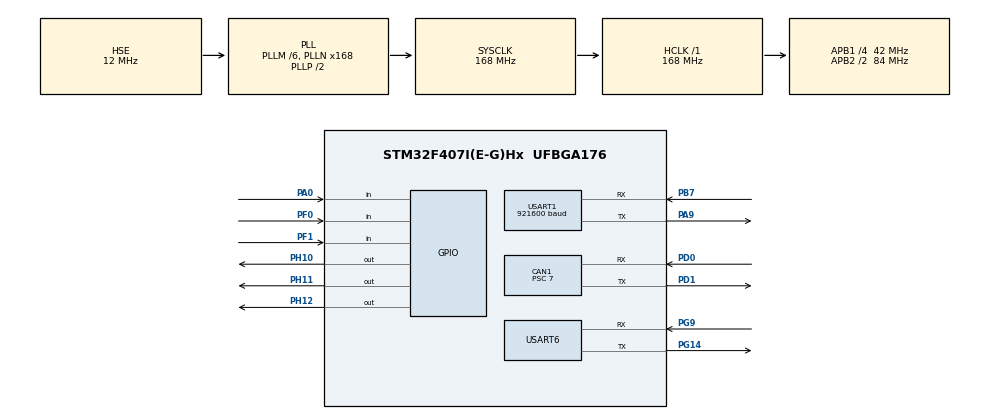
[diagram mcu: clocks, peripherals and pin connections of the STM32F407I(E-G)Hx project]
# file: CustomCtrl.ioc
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CAN1.ABOM=ENABLE
CAN1.BS1=CAN_BS1_2TQ
CAN1.BS2=CAN_BS2_3TQ
CAN1.CalculateBaudRate=999999
CAN1.CalculateTimeBit=1000
CAN1.CalculateTimeQuantum=166.66666666666669
CAN1.Prescaler=7
Dma.Request0=USART1_RX
Dma.Request1=USART1_TX
Dma.Request2=USART6_RX
Dma.Request3=USART6_TX
Dma.USART1_RX.0.Direction=DMA_PERIPH_TO_MEMORY
Dma.USART1_RX.0.FIFOMode=DMA_FIFOMODE_DISABLE
Dma.USART1_RX.0.Instance=DMA2_Stream2
Dma.USART1_RX.0.MemDataAlignment=DMA_MDATAALIGN_BYTE
Dma.USART1_RX.0.MemInc=DMA_MINC_ENABLE
Dma.USART1_RX.0.Mode=DMA_NORMAL
Dma.USART1_RX.0.PeriphDataAlignment=DMA_PDATAALIGN_BYTE
Dma.USART1_RX.0.PeriphInc=DMA_PINC_DISABLE
Dma.USART1_RX.0.Priority=DMA_PRIORITY_LOW
Dma.USART1_TX.1.Direction=DMA_MEMORY_TO_PERIPH
Dma.USART1_TX.1.FIFOMode=DMA_FIFOMODE_DISABLE
Dma.USART1_TX.1.Instance=DMA2_Stream7
Dma.USART1_TX.1.MemDataAlignment=DMA_MDATAALIGN_BYTE
Dma.USART1_TX.1.MemInc=DMA_MINC_ENABLE
Dma.USART1_TX.1.Mode=DMA_NORMAL
Dma.USART1_TX.1.PeriphDataAlignment=DMA_PDATAALIGN_BYTE
Dma.USART1_TX.1.PeriphInc=DMA_PINC_DISABLE
Dma.USART1_TX.1.Priority=DMA_PRIORITY_LOW
Dma.USART6_RX.2.Direction=DMA_PERIPH_TO_MEMORY
Dma.USART6_RX.2.FIFOMode=DMA_FIFOMODE_DISABLE
Dma.USART6_RX.2.Instance=DMA2_Stream1
Dma.USART6_RX.2.MemDataAlignment=DMA_MDATAALIGN_BYTE
Dma.USART6_RX.2.MemInc=DMA_MINC_ENABLE
Dma.USART6_RX.2.Mode=DMA_NORMAL
Dma.USART6_RX.2.PeriphDataAlignment=DMA_PDATAALIGN_BYTE
Dma.USART6_RX.2.PeriphInc=DMA_PINC_DISABLE
Dma.USART6_RX.2.Priority=DMA_PRIORITY_LOW
Dma.USART6_TX.3.Direction=DMA_MEMORY_TO_PERIPH
Dma.USART6_TX.3.FIFOMode=DMA_FIFOMODE_DISABLE
Dma.USART6_TX.3.Instance=DMA2_Stream6
Dma.USART6_TX.3.MemDataAlignment=DMA_MDATAALIGN_BYTE
Dma.USART6_TX.3.MemInc=DMA_MINC_ENABLE
Dma.USART6_TX.3.Mode=DMA_NORMAL
Dma.USART6_TX.3.PeriphDataAlignment=DMA_PDATAALIGN_BYTE
Dma.USART6_TX.3.PeriphInc=DMA_PINC_DISABLE
Dma.USART6_TX.3.Priority=DMA_PRIORITY_LOW
FREERTOS.Mutexes01=CANmutex,Dynamic,NULL,Available
FREERTOS.Tasks01=defaultTask,48,256,StartDefaultTask,As weak,NULL,Dynamic,NULL,NULL;OS_ServosTask,24,256,ServosTask,As weak,NULL,Dynamic,NULL,NULL;OS_DetectTask,24,256,DetectTask,As weak,NULL,Dynamic,NULL,NULL;OS_ButtonTask,24,256,ButtonTask,As weak,NULL,Dynamic,NULL,NULL;OS_Transmit,24,384,TransmitTask,As weak,NULL,Dynamic,NULL,NULL;OS_ReceiveTask,24,256,ReceiveTask,As weak,NULL,Dynamic,NULL,NULL
FREERTOS.configENABLE_FPU=1
Mcu.Family=STM32F4
Mcu.Name=STM32F407I(E-G)Hx
Mcu.Package=UFBGA176
NVIC.CAN1_RX0_IRQn=true\:5\:0\:false\:false\:true\:true\:true\:true\:true
NVIC.DMA2_Stream1_IRQn=true\:5\:0\:false\:false\:true\:true\:false\:true\:true
NVIC.DMA2_Stream2_IRQn=true\:5\:0\:false\:false\:true\:true\:false\:true\:true
NVIC.DMA2_Stream6_IRQn=true\:5\:0\:false\:false\:true\:true\:false\:true\:true
NVIC.DMA2_Stream7_IRQn=true\:5\:0\:false\:false\:true\:true\:false\:true\:true
NVIC.PriorityGroup=NVIC_PRIORITYGROUP_4
NVIC.TIM8_TRG_COM_TIM14_IRQn=true\:15\:0\:false\:false\:true\:false\:false\:true\:true
NVIC.TimeBase=TIM8_TRG_COM_TIM14_IRQn
NVIC.TimeBaseIP=TIM14
NVIC.USART1_IRQn=true\:5\:0\:false\:false\:true\:true\:true\:true\:true
NVIC.USART6_IRQn=true\:5\:0\:false\:false\:true\:true\:true\:true\:true
PA0-WKUP.Signal=GPIO_Input
PA13.Mode=Serial_Wire
PA13.Signal=SYS_JTMS-SWDIO
PA14.Mode=Serial_Wire
PA14.Signal=SYS_JTCK-SWCLK
PA9.Mode=Asynchronous
PA9.Signal=USART1_TX
PB7.Mode=Asynchronous
PB7.Signal=USART1_RX
PD0.Mode=CAN_Activate
PD0.Signal=CAN1_RX
PD1.Mode=CAN_Activate
PD1.Signal=CAN1_TX
PF0.GPIO_PuPd=GPIO_PULLUP
PF0.Signal=GPIO_Input
PF1.GPIO_PuPd=GPIO_PULLUP
PF1.Signal=GPIO_Input
PG14.Mode=Asynchronous
PG14.Signal=USART6_TX
PG9.Mode=Asynchronous
PG9.Signal=USART6_RX
PH0-OSC_IN.Mode=HSE-External-Oscillator
PH0-OSC_IN.Signal=RCC_OSC_IN
PH1-OSC_OUT.Mode=HSE-External-Oscillator
PH1-OSC_OUT.Signal=RCC_OSC_OUT
PH10.Signal=GPIO_Output
PH11.Signal=GPIO_Output
PH12.Signal=GPIO_Output
ProjectManager.HeapSize=0x200
ProjectManager.StackSize=0x400
ProjectManager.TargetToolchain=MDK-ARM V5.32
RCC.48MHZClocksFreq_Value=84000000
RCC.AHBFreq_Value=168000000
RCC.APB1CLKDivider=RCC_HCLK_DIV4
RCC.APB1Freq_Value=42000000
RCC.APB1TimFreq_Value=84000000
RCC.APB2CLKDivider=RCC_HCLK_DIV2
RCC.APB2Freq_Value=84000000
RCC.APB2TimFreq_Value=168000000
RCC.CortexFreq_Value=168000000
RCC.HCLKFreq_Value=168000000
RCC.HSE_VALUE=12000000
RCC.HSI_VALUE=16000000
RCC.LSE_VALUE=32768
RCC.PLLM=6
RCC.PLLN=168
RCC.PLLSourceVirtual=RCC_PLLSOURCE_HSE
RCC.SYSCLKFreq_VALUE=168000000
RCC.SYSCLKSource=RCC_SYSCLKSOURCE_PLLCLK
RCC.VCOOutputFreq_Value=336000000
USART1.BaudRate=921600
USART1.VirtualMode=VM_ASYNC
USART6.VirtualMode=VM_ASYNC
VP_FREERTOS_VS_CMSIS_V2.Mode=CMSIS_V2
VP_SYS_VS_tim14.Mode=TIM14
board=custom

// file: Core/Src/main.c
/* USER CODE BEGIN Header */
/**
  ******************************************************************************
  * @file           : main.c
  * @brief          : Main program body
  ******************************************************************************
  * @attention
  *
  * Copyright (c) 2025 STMicroelectronics.
  * All rights reserved.
  *
  * This software is licensed under terms that can be found in the LICENSE file
  * in the root directory of this software component.
  * If no LICENSE file comes with this software, it is provided AS-IS.
  *
  ******************************************************************************
  */
/* USER CODE END Header */
#include "main.h"
#include "cmsis_os.h"
#include "can.h"
#include "dma.h"
#include "usart.h"
#include "gpio.h"

void SystemClock_Config(void);
void MX_FREERTOS_Init(void);

int main(void)
{

  /* MCU Configuration--------------------------------------------------------*/

  /* Reset of all peripherals, Initializes the Flash interface and the Systick. */
  HAL_Init();

  /* Configure the system clock */
  SystemClock_Config();

  /* Initialize all configured peripherals */
  MX_GPIO_Init();
  MX_DMA_Init();
  MX_CAN1_Init();
  MX_USART1_UART_Init();
  MX_USART6_UART_Init();
  /* USER CODE BEGIN 2 */
//  HAL_GPIO_TogglePin(GPIOH, GPIO_PIN_10);
//  HAL_GPIO_TogglePin(GPIOH, GPIO_PIN_11);
  /* USER CODE END 2 */

  /* Init scheduler */
  osKernelInitialize();

  /* Call init function for freertos objects (in cmsis_os2.c) */
  MX_FREERTOS_Init();

  /* Start scheduler */
  osKernelStart();

  /* We should never get here as control is now taken by the scheduler */

  /* Infinite loop */
  while (1)
  {

  }
}

void SystemClock_Config(void)
{
  RCC_OscInitTypeDef RCC_OscInitStruct = {0};
  RCC_ClkInitTypeDef RCC_ClkInitStruct = {0};

  /** Configure the main internal regulator output voltage
  */
  __HAL_RCC_PWR_CLK_ENABLE();
  __HAL_PWR_VOLTAGESCALING_CONFIG(PWR_REGULATOR_VOLTAGE_SCALE1);

  /** Initializes the RCC Oscillators according to the specified parameters
  * in the RCC_OscInitTypeDef structure.
  */
  RCC_OscInitStruct.OscillatorType = RCC_OSCILLATORTYPE_HSE;
  RCC_OscInitStruct.HSEState = RCC_HSE_ON;
  RCC_OscInitStruct.PLL.PLLState = RCC_PLL_ON;
  RCC_OscInitStruct.PLL.PLLSource = RCC_PLLSOURCE_HSE;
  RCC_OscInitStruct.PLL.PLLM = 6;
  RCC_OscInitStruct.PLL.PLLN = 168;
  RCC_OscInitStruct.PLL.PLLP = RCC_PLLP_DIV2;
  RCC_OscInitStruct.PLL.PLLQ = 4;
  if (HAL_RCC_OscConfig(&RCC_OscInitStruct) != HAL_OK)
  {
    Error_Handler();
  }

  /** Initializes the CPU, AHB and APB buses clocks
  */
  RCC_ClkInitStruct.ClockType = RCC_CLOCKTYPE_HCLK|RCC_CLOCKTYPE_SYSCLK
                              |RCC_CLOCKTYPE_PCLK1|RCC_CLOCKTYPE_PCLK2;
  RCC_ClkInitStruct.SYSCLKSource = RCC_SYSCLKSOURCE_PLLCLK;
  RCC_ClkInitStruct.AHBCLKDivider = RCC_SYSCLK_DIV1;
  RCC_ClkInitStruct.APB1CLKDivider = RCC_HCLK_DIV4;
  RCC_ClkInitStruct.APB2CLKDivider = RCC_HCLK_DIV2;

  if (HAL_RCC_ClockConfig(&RCC_ClkInitStruct, FLASH_LATENCY_5) != HAL_OK)
  {
    Error_Handler();
  }
}

void HAL_TIM_PeriodElapsedCallback(TIM_HandleTypeDef *htim)
{
  if (htim->Instance == TIM14) {
    HAL_IncTick();
  }
}

void Error_Handler(void)
{
  __disable_irq();
  while (1)
  {
  }
}

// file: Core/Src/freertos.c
/* USER CODE BEGIN Header */
/**
  ******************************************************************************
  * File Name          : freertos.c
  * Description        : Code for freertos applications
  ******************************************************************************
  * @attention
  *
  * Copyright (c) 2025 STMicroelectronics.
  * All rights reserved.
  *
  * This software is licensed under terms that can be found in the LICENSE file
  * in the root directory of this software component.
  * If no LICENSE file comes with this software, it is provided AS-IS.
  *
  ******************************************************************************
  */
/* USER CODE END Header */

#include "FreeRTOS.h"
#include "task.h"
#include "main.h"
#include "cmsis_os.h"

/* Definitions for defaultTask */
osThreadId_t defaultTaskHandle;
const osThreadAttr_t defaultTask_attributes = {
  .name = "defaultTask",
  .stack_size = 256 * 4,
  .priority = (osPriority_t) osPriorityRealtime,
};
/* Definitions for OS_ServosTask */
osThreadId_t OS_ServosTaskHandle;
const osThreadAttr_t OS_ServosTask_attributes = {
  .name = "OS_ServosTask",
  .stack_size = 256 * 4,
  .priority = (osPriority_t) osPriorityNormal,
};
/* Definitions for OS_DetectTask */
osThreadId_t OS_DetectTaskHandle;
const osThreadAttr_t OS_DetectTask_attributes = {
  .name = "OS_DetectTask",
  .stack_size = 256 * 4,
  .priority = (osPriority_t) osPriorityNormal,
};
/* Definitions for OS_ButtonTask */
osThreadId_t OS_ButtonTaskHandle;
const osThreadAttr_t OS_ButtonTask_attributes = {
  .name = "OS_ButtonTask",
  .stack_size = 256 * 4,
  .priority = (osPriority_t) osPriorityNormal,
};
/* Definitions for OS_Transmit */
osThreadId_t OS_TransmitHandle;
const osThreadAttr_t OS_Transmit_attributes = {
  .name = "OS_Transmit",
  .stack_size = 384 * 4,
  .priority = (osPriority_t) osPriorityNormal,
};
/* Definitions for OS_ReceiveTask */
osThreadId_t OS_ReceiveTaskHandle;
const osThreadAttr_t OS_ReceiveTask_attributes = {
  .name = "OS_ReceiveTask",
  .stack_size = 256 * 4,
  .priority = (osPriority_t) osPriorityNormal,
};
/* Definitions for CANmutex */
osMutexId_t CANmutexHandle;
const osMutexAttr_t CANmutex_attributes = {
  .name = "CANmutex"
};

void StartDefaultTask(void *argument);
void ServosTask(void *argument);
void DetectTask(void *argument);
void ButtonTask(void *argument);
void TransmitTask(void *argument);
void ReceiveTask(void *argument);

void MX_FREERTOS_Init(void); /* (MISRA C 2004 rule 8.1) */

void MX_FREERTOS_Init(void) {
  /* Create the mutex(es) */
  /* creation of CANmutex */
  CANmutexHandle = osMutexNew(&CANmutex_attributes);

  /* Create the thread(s) */
  /* creation of defaultTask */
  defaultTaskHandle = osThreadNew(StartDefaultTask, NULL, &defaultTask_attributes);

  /* creation of OS_ServosTask */
  OS_ServosTaskHandle = osThreadNew(ServosTask, NULL, &OS_ServosTask_attributes);

  /* creation of OS_DetectTask */
  OS_DetectTaskHandle = osThreadNew(DetectTask, NULL, &OS_DetectTask_attributes);

  /* creation of OS_ButtonTask */
  OS_ButtonTaskHandle = osThreadNew(ButtonTask, NULL, &OS_ButtonTask_attributes);

  /* creation of OS_Transmit */
  OS_TransmitHandle = osThreadNew(TransmitTask, NULL, &OS_Transmit_attributes);

  /* creation of OS_ReceiveTask */
  OS_ReceiveTaskHandle = osThreadNew(ReceiveTask, NULL, &OS_ReceiveTask_attributes);

}

__weak void StartDefaultTask(void *argument)
{
  for(;;)
  {
    osDelay(1);
  }
}

__weak void ServosTask(void *argument)
{
  for(;;)
  {
    osDelay(1);
  }
}

__weak void DetectTask(void *argument)
{
  for(;;)
  {
    osDelay(1);
  }
}

__weak void ButtonTask(void *argument)
{
  for(;;)
  {
    osDelay(1);
  }
}

__weak void TransmitTask(void *argument)
{
  for(;;)
  {
    osDelay(1);
  }
}

__weak void ReceiveTask(void *argument)
{
  for(;;)
  {
    osDelay(1);
  }
}
